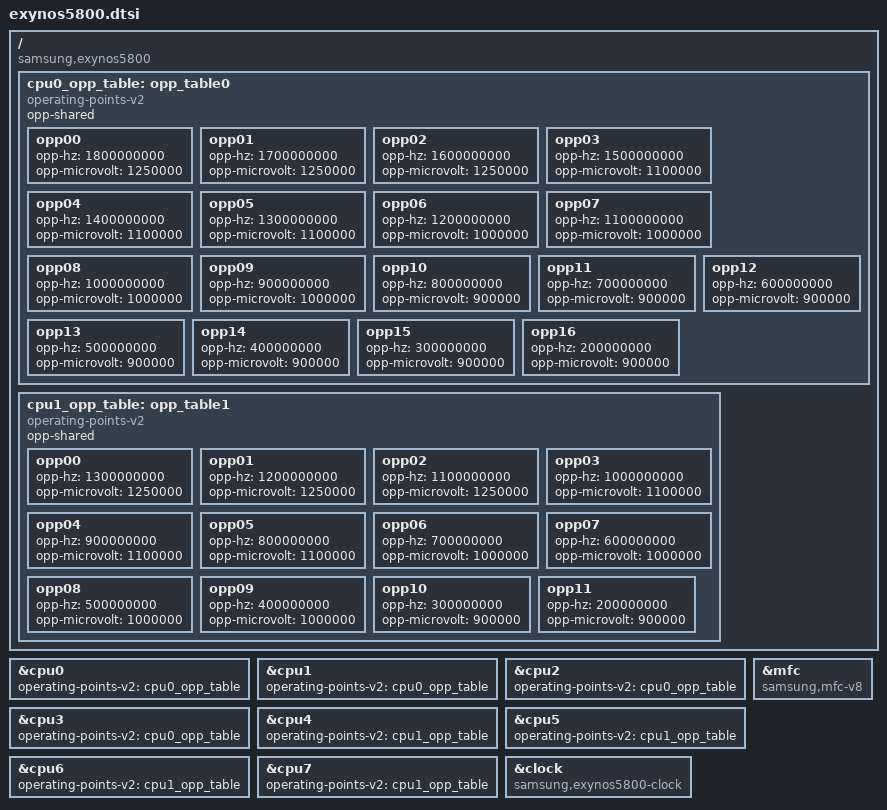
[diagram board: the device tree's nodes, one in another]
/*
 * SAMSUNG EXYNOS5800 SoC device tree source
 *
 * Copyright (c) 2014 Samsung Electronics Co., Ltd.
 *		http://www.samsung.com
 *
 * SAMSUNG EXYNOS5800 SoC device nodes are listed in this file.
 * EXYNOS5800 based board files can include this file and provide
 * values for board specfic bindings.
 *
 * This program is free software; you can redistribute it and/or modify
 * it under the terms of the GNU General Public License version 2 as
 * published by the Free Software Foundation.
 */

#include "exynos5420.dtsi"

/ {
	compatible = "samsung,exynos5800", "samsung,exynos5";

	cpu0_opp_table: opp_table0 {
		compatible = "operating-points-v2";
		opp-shared;
		opp00 {
			opp-hz = /bits/ 64 <1800000000>;
			opp-microvolt = <1250000>;
		};
		opp01 {
			opp-hz = /bits/ 64 <1700000000>;
			opp-microvolt = <1250000>;
		};
		opp02 {
			opp-hz = /bits/ 64 <1600000000>;
			opp-microvolt = <1250000>;
		};
		opp03 {
			opp-hz = /bits/ 64 <1500000000>;
			opp-microvolt = <1100000>;
		};
		opp04 {
			opp-hz = /bits/ 64 <1400000000>;
			opp-microvolt = <1100000>;
		};
		opp05 {
			opp-hz = /bits/ 64 <1300000000>;
			opp-microvolt = <1100000>;
		};
		opp06 {
			opp-hz = /bits/ 64 <1200000000>;
			opp-microvolt = <1000000>;
		};
		opp07 {
			opp-hz = /bits/ 64 <1100000000>;
			opp-microvolt = <1000000>;
		};
		opp08 {
			opp-hz = /bits/ 64 <1000000000>;
			opp-microvolt = <1000000>;
		};
		opp09 {
			opp-hz = /bits/ 64 <900000000>;
			opp-microvolt = <1000000>;
		};
		opp10 {
			opp-hz = /bits/ 64 <800000000>;
			opp-microvolt = <900000>;
		};
		opp11 {
			opp-hz = /bits/ 64 <700000000>;
			opp-microvolt = <900000>;
		};
		opp12 {
			opp-hz = /bits/ 64 <600000000>;
			opp-microvolt = <900000>;
		};
		opp13 {
			opp-hz = /bits/ 64 <500000000>;
			opp-microvolt = <900000>;
		};
		opp14 {
			opp-hz = /bits/ 64 <400000000>;
			opp-microvolt = <900000>;
		};
		opp15 {
			opp-hz = /bits/ 64 <300000000>;
			opp-microvolt = <900000>;
		};
		opp16 {
			opp-hz = /bits/ 64 <200000000>;
			opp-microvolt = <900000>;
		};
	};

	cpu1_opp_table: opp_table1 {
		compatible = "operating-points-v2";
		opp-shared;
		opp00 {
			opp-hz = /bits/ 64 <1300000000>;
			opp-microvolt = <1250000>;
		};
		opp01 {
			opp-hz = /bits/ 64 <1200000000>;
			opp-microvolt = <1250000>;
		};
		opp02 {
			opp-hz = /bits/ 64 <1100000000>;
			opp-microvolt = <1250000>;
		};
		opp03 {
			opp-hz = /bits/ 64 <1000000000>;
			opp-microvolt = <1100000>;
		};
		opp04 {
			opp-hz = /bits/ 64 <900000000>;
			opp-microvolt = <1100000>;
		};
		opp05 {
			opp-hz = /bits/ 64 <800000000>;
			opp-microvolt = <1100000>;
		};
		opp06 {
			opp-hz = /bits/ 64 <700000000>;
			opp-microvolt = <1000000>;
		};
		opp07 {
			opp-hz = /bits/ 64 <600000000>;
			opp-microvolt = <1000000>;
		};
		opp08 {
			opp-hz = /bits/ 64 <500000000>;
			opp-microvolt = <1000000>;
		};
		opp09 {
			opp-hz = /bits/ 64 <400000000>;
			opp-microvolt = <1000000>;
		};
		opp10 {
			opp-hz = /bits/ 64 <300000000>;
			opp-microvolt = <900000>;
		};
		opp11 {
			opp-hz = /bits/ 64 <200000000>;
			opp-microvolt = <900000>;
		};
	};
};

&cpu0 { operating-points-v2 = <&cpu0_opp_table>; };
&cpu1 { operating-points-v2 = <&cpu0_opp_table>; };
&cpu2 { operating-points-v2 = <&cpu0_opp_table>; };
&cpu3 { operating-points-v2 = <&cpu0_opp_table>; };

&cpu4 { operating-points-v2 = <&cpu1_opp_table>; };
&cpu5 { operating-points-v2 = <&cpu1_opp_table>; };
&cpu6 { operating-points-v2 = <&cpu1_opp_table>; };
&cpu7 { operating-points-v2 = <&cpu1_opp_table>; };

&clock {
	compatible = "samsung,exynos5800-clock";
};

&mfc {
	compatible = "samsung,mfc-v8";
};
